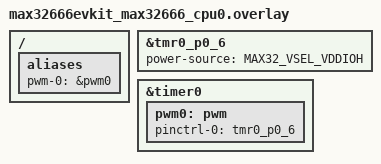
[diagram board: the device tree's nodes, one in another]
/*
 * Copyright (c) 2024 Analog Devices, Inc.
 *
 * SPDX-License-Identifier: Apache-2.0
 */

/ {
	aliases {
		pwm-0 = &pwm0;
	};
};

&tmr0_p0_6 {
	power-source = <MAX32_VSEL_VDDIOH>;
};

&timer0 {
	status = "okay";
	pwm0: pwm {
		status = "okay";
		pinctrl-0 = <&tmr0_p0_6>;
		pinctrl-names = "default";
	};
};
